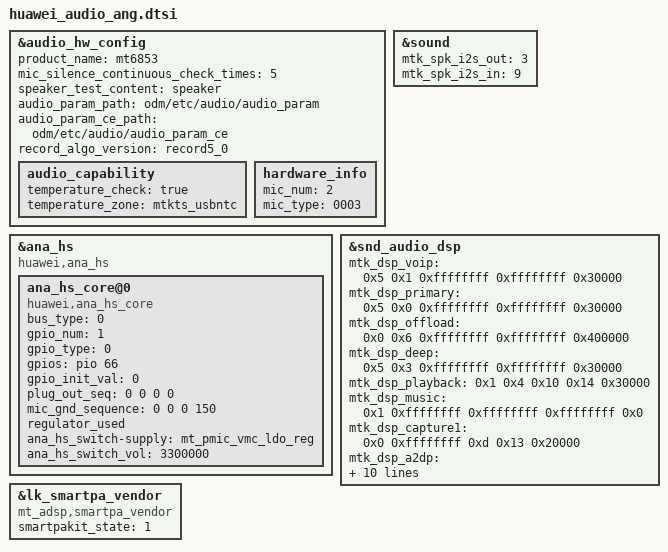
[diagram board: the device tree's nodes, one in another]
#include "device_boxid.dtsi"
#include "smartpa.dtsi"

&audio_hw_config {
	product_name = "mt6853";
	mic_silence_continuous_check_times = "5";
	speaker_test_content = "speaker";
	audio_param_path = "odm/etc/audio/audio_param";
	audio_param_ce_path = "odm/etc/audio/audio_param_ce";
	record_algo_version = "record5_0";

	audio_capability {
		/* for smartpa calibrate temperature check use */
		temperature_check = "true";
		temperature_zone = "mtkts_usbntc";
	};
	hardware_info {
		mic_num = "2";
		mic_type = "0003"; /* 0001 sub mic   0002 main mic   0004 sub mic2   0008 main mic2 */
	};
};

&ana_hs {
	compatible = "huawei,ana_hs";
	status = "ok";
	ana_hs_core@0 {
		compatible = "huawei,ana_hs_core";
		bus_type = <0>; // 0: gpio,  1: i2c
		//if use gpio
		gpio_num = <1>;
		gpio_type = <0>; // 0: SOC,  1: codec
		gpios = <&pio 66 0>;  // gpio_mos_switch[H:mos to hs, L:mos to usb], gpio_mic_gnd[H:audio sbu1->mic, audio sbu2->gnd]
		gpio_init_val = <0>;  // 0 for low, 1 for high for gpio direction output

		//plug_out sequence
		plug_out_seq = <
			0 0 0 0
		>;
		//mic_gnd_switch used gpio
		mic_gnd_sequence = <
			0 0 0 150
		>;
		regulator_used;
		ana_hs_switch-supply = <&mt_pmic_vmc_ldo_reg>; // mt6360-ldo3
		ana_hs_switch_vol = <3300000>;
		status = "ok";
	};
};

&sound {
		mtk_spk_i2s_out = <3>;
		mtk_spk_i2s_in = <9>; //9 means 32bit, 0 means 24bit.
};

/* feature : $enable $dl_mem $ul_mem $ref_mem $size */
&snd_audio_dsp {
	mtk_dsp_voip = <0x5 0x1 0xffffffff 0xffffffff 0x30000>;
	mtk_dsp_primary = <0x5 0x0 0xffffffff 0xffffffff 0x30000>;
	mtk_dsp_offload = <0x0 0x6 0xffffffff 0xffffffff 0x400000>;
	mtk_dsp_deep = <0x5 0x3 0xffffffff 0xffffffff 0x30000>;
	mtk_dsp_playback = <0x1 0x4 0x10 0x14 0x30000>;
	mtk_dsp_music = <0x1 0xffffffff 0xffffffff 0xffffffff 0x0>;
	mtk_dsp_capture1 = <0x0 0xffffffff 0xd 0x13 0x20000>;
	mtk_dsp_a2dp = <0x0 0xffffffff 0xffffffff 0xffffffff 0x40000>;
	mtk_dsp_dataprovider = <0x0 0xffffffff 0xf 0xffffffff 0x30000>;
	mtk_dsp_call_final = <0x5 0x0 0x10 0x14 0x18000>;
	mtk_dsp_fast = <0x5 0x2 0xffffffff 0xffffffff 0x5000>;
	mtk_dsp_ktv = <0x0 0x8 0x12 0xffffffff 0x10000>;
	mtk_dsp_ver = <0x1>;
	swdsp_smartpa_process_enable = <0x5>;
	mtk_dsp_mem_afe = <0x1 0x40000>; /* always enable */
};

&lk_smartpa_vendor {
	compatible = "mt_adsp,smartpa_vendor";
	smartpakit_state = <1>; // 0-not support, 1-support
};
